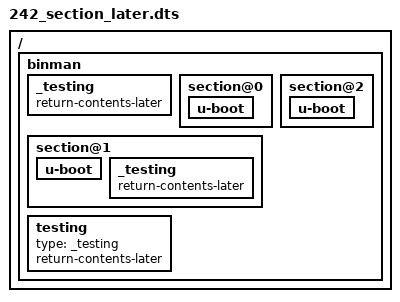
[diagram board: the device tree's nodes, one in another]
// SPDX-License-Identifier: GPL-2.0+

/dts-v1/;

/ {
	#address-cells = <1>;
	#size-cells = <1>;

	binman {
		_testing {
			return-contents-later;
		};
		section@0 {
			u-boot {
			};
		};
		section@1 {
			u-boot {
			};
			_testing {
				return-contents-later;
			};
		};
		section@2 {
			u-boot {
			};
		};
		testing {
			type = "_testing";
			return-contents-later;
		};
	};
};
